VERSION "f33"
NS_ :

BS_:
BU_: RR RL FL FR GEN

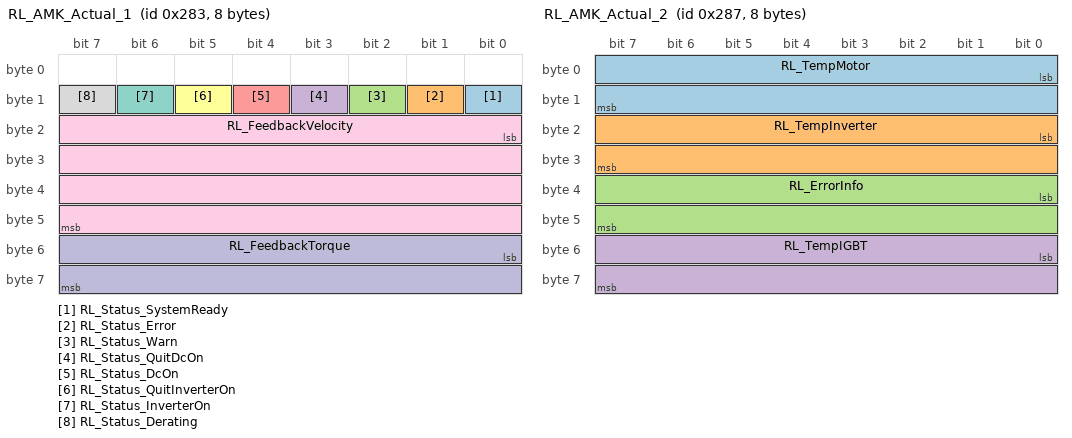
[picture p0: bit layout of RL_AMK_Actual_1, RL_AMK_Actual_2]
BO_ 643 RL_AMK_Actual_1: 8 RL
 SG_ RL_Status_SystemReady : 8|1@1+ (1,0) [0|1] "" Vector__XXX
 SG_ RL_Status_Error : 9|1@1+ (1,0) [0|1] "" Vector__XXX
 SG_ RL_Status_Warn : 10|1@1+ (1,0) [0|1] "" Vector__XXX
 SG_ RL_Status_QuitDcOn : 11|1@1+ (1,0) [0|1] "" Vector__XXX
 SG_ RL_Status_DcOn : 12|1@1+ (1,0) [0|1] "" Vector__XXX
 SG_ RL_Status_QuitInverterOn : 13|1@1+ (1,0) [0|1] "" Vector__XXX
 SG_ RL_Status_InverterOn : 14|1@1+ (1,0) [0|1] "" Vector__XXX
 SG_ RL_Status_Derating : 15|1@1+ (1,0) [0|1] "" Vector__XXX
 SG_ RL_FeedbackVelocity : 16|32@1- (0.0001,0) [-100000.0|100000.0] "rpm" Vector__XXX
 SG_ RL_FeedbackTorque : 48|16@1- (0.1,0) [-3000.0|3000.0] "% Mn" Vector__XXX

BO_ 647 RL_AMK_Actual_2: 8 RL
 SG_ RL_TempMotor : 0|16@1- (0.1,0) [-3276.8|3276.7] "degC" Vector__XXX
 SG_ RL_TempInverter : 16|16@1- (0.1,0) [-3276.8|3276.7] "" Vector__XXX
 SG_ RL_ErrorInfo : 32|16@1+ (1,0) [0|65535] "" Vector__XXX
 SG_ RL_TempIGBT : 48|16@1- (0.1,0) [-3276.8|3276.7] "" Vector__XXX

BO_ 657 RL_AMK_RITSet1: 8 RL
 SG_ RL_ErrorList1 : 0|32@1+ (1,0) [0|0] "" Vector__XXX
 SG_ RL_ErrorList2 : 32|32@1+ (1,0) [0|0] "" Vector__XXX

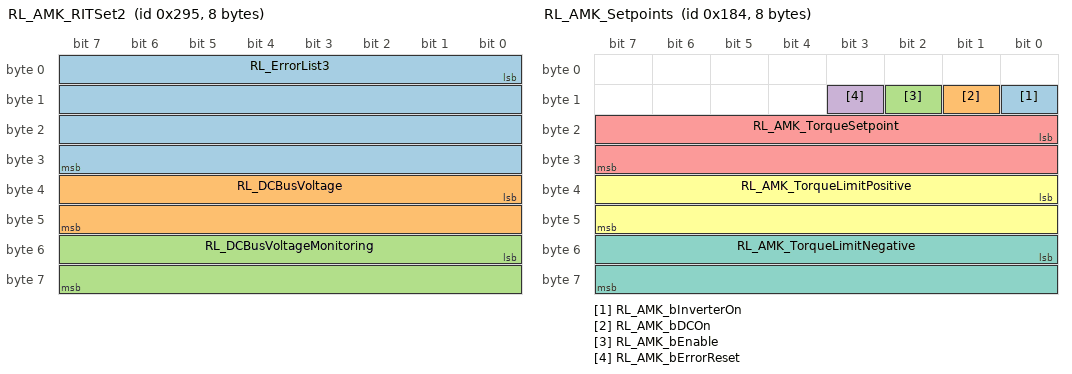
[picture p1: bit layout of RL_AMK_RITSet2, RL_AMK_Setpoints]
BO_ 661 RL_AMK_RITSet2: 8 RL
 SG_ RL_ErrorList3 : 0|32@1+ (1,0) [0|0] "" Vector__XXX
 SG_ RL_DCBusVoltage : 32|16@1+ (1,0) [0|4096] "V" Vector__XXX
 SG_ RL_DCBusVoltageMonitoring : 48|16@1+ (0.1,0) [0|4096] "V" Vector__XXX

BO_ 665 RL_AMK_RITSet3: 4 RL
 SG_ RL_ActivePower : 0|32@1- (1,0) [-2147483648|2147483647] "W" Vector__XXX

BO_ 669 RL_AMK_RITSet4: 4 RL
 SG_ RL_ActualPowerBipolar : 0|32@1- (1,0) [0|0] "W" Vector__XXX

BO_ 673 RL_AMK_RIT_Set5: 4 RL
 SG_ RL_MagnetizingCurrent: 0|32@1- (0.001,0) [0|0] "A" Vector__XXX

BO_ 677 RL_AMK_RIT_Set6: 4 RL
 SG_ RL_TorqueCurrentFeedback: 0|32@1- (0.001,0) [0|0] "A" Vector__XXX

BO_ 388 RL_AMK_Setpoints: 8 RL
 SG_ RL_AMK_bInverterOn : 8|1@1+ (1,0) [0|1] "" Vector__XXX
 SG_ RL_AMK_bDCOn : 9|1@1+ (1,0) [0|1] "" Vector__XXX
 SG_ RL_AMK_bEnable : 10|1@1+ (1,0) [0|1] "" Vector__XXX
 SG_ RL_AMK_bErrorReset : 11|1@1+ (1,0) [0|1] "" Vector__XXX
 SG_ RL_AMK_TorqueSetpoint : 16|16@1- (0.1, 0) [-1000|1000] "% Mn" Vector__XXX
 SG_ RL_AMK_TorqueLimitPositive : 32|16@1- (0.1, 0) [-3000|3000] "% Mn" Vector__XXX
 SG_ RL_AMK_TorqueLimitNegative : 48|16@1- (0.1, 0) [-3000|3000] "% Mn" Vector__XXX

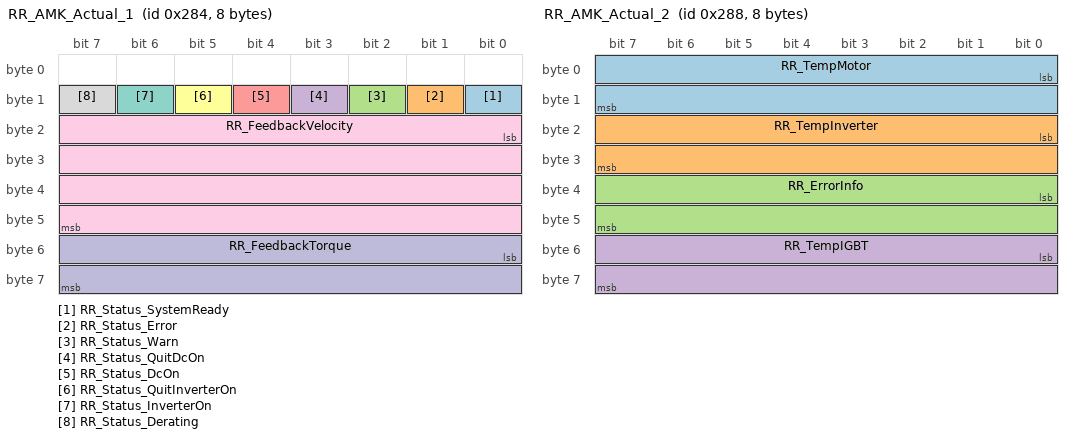
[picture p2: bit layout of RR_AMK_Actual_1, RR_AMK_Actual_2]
BO_ 644 RR_AMK_Actual_1: 8 RR
 SG_ RR_Status_SystemReady : 8|1@1+ (1,0) [0|1] "" Vector__XXX
 SG_ RR_Status_Error : 9|1@1+ (1,0) [0|1] "" Vector__XXX
 SG_ RR_Status_Warn : 10|1@1+ (1,0) [0|1] "" Vector__XXX
 SG_ RR_Status_QuitDcOn : 11|1@1+ (1,0) [0|1] "" Vector__XXX
 SG_ RR_Status_DcOn : 12|1@1+ (1,0) [0|1] "" Vector__XXX
 SG_ RR_Status_QuitInverterOn : 13|1@1+ (1,0) [0|1] "" Vector__XXX
 SG_ RR_Status_InverterOn : 14|1@1+ (1,0) [0|1] "" Vector__XXX
 SG_ RR_Status_Derating : 15|1@1+ (1,0) [0|1] "" Vector__XXX
 SG_ RR_FeedbackVelocity : 16|32@1- (0.0001,0) [-100000.0|100000.0] "rpm" Vector__XXX
 SG_ RR_FeedbackTorque : 48|16@1- (0.1,0) [-3000.0|3000.0] "% Mn" Vector__XXX

BO_ 648 RR_AMK_Actual_2: 8 RR
 SG_ RR_TempMotor : 0|16@1- (0.1,0) [-3276.8|3276.7] "degC" Vector__XXX
 SG_ RR_TempInverter : 16|16@1- (0.1,0) [-3276.8|3276.7] "" Vector__XXX
 SG_ RR_ErrorInfo : 32|16@1+ (1,0) [0|65535] "" Vector__XXX
 SG_ RR_TempIGBT : 48|16@1- (0.1,0) [-3276.8|3276.7] "" Vector__XXX

BO_ 658 RR_AMK_RITSet1: 8 RR
 SG_ RR_ErrorList1 : 0|32@1+ (1,0) [0|0] "" Vector__XXX
 SG_ RR_ErrorList2 : 32|32@1+ (1,0) [0|0] "" Vector__XXX

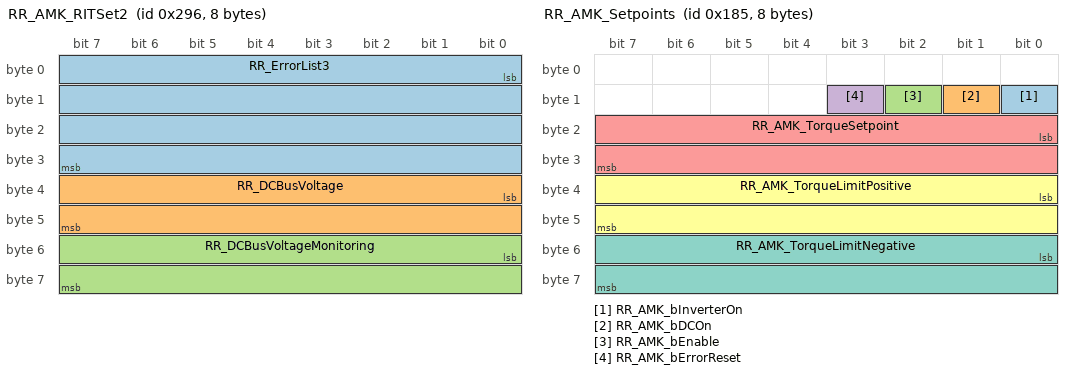
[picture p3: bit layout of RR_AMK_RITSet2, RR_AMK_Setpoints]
BO_ 662 RR_AMK_RITSet2: 8 RR
 SG_ RR_ErrorList3 : 0|32@1+ (1,0) [0|0] "" Vector__XXX
 SG_ RR_DCBusVoltage : 32|16@1+ (1,0) [0|4096] "V" Vector__XXX
 SG_ RR_DCBusVoltageMonitoring : 48|16@1+ (0.1,0) [0|4096] "V" Vector__XXX

BO_ 666 RR_AMK_RITSet3: 4 RR
 SG_ RR_ActivePower : 0|32@1- (1,0) [-2147483648|2147483647] "W" Vector__XXX

BO_ 670 RR_AMK_RITSet4: 4 RR
 SG_ RR_ActualPowerBipolar : 0|32@1- (1,0) [0|0] "W" Vector__XXX

BO_ 674 RR_AMK_RIT_Set5: 4 RR
 SG_ RR_MagnetizingCurrent: 0|32@1- (0.001,0) [0|0] "A" Vector__XXX

BO_ 678 RR_AMK_RIT_Set6: 4 RR
 SG_ RR_TorqueCurrentFeedback: 0|32@1- (0.001,0) [0|0] "A" Vector__XXX

BO_ 389 RR_AMK_Setpoints: 8 RR
 SG_ RR_AMK_bInverterOn : 8|1@1+ (1,0) [0|1] "" Vector__XXX
 SG_ RR_AMK_bDCOn : 9|1@1+ (1,0) [0|1] "" Vector__XXX
 SG_ RR_AMK_bEnable : 10|1@1+ (1,0) [0|1] "" Vector__XXX
 SG_ RR_AMK_bErrorReset : 11|1@1+ (1,0) [0|1] "" Vector__XXX
 SG_ RR_AMK_TorqueSetpoint : 16|16@1- (0.1, 0) [-1000|1000] "% Mn" Vector__XXX
 SG_ RR_AMK_TorqueLimitPositive : 32|16@1- (0.1, 0) [-3000|3000] "% Mn" Vector__XXX
 SG_ RR_AMK_TorqueLimitNegative : 48|16@1- (0.1, 0) [-3000|3000] "% Mn" Vector__XXX

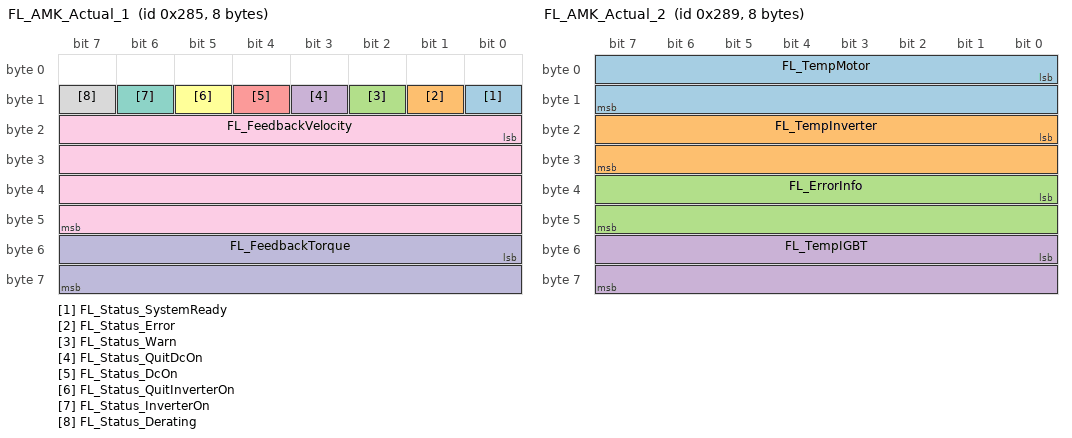
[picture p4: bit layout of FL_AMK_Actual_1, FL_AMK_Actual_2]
BO_ 645 FL_AMK_Actual_1: 8 FL
 SG_ FL_Status_SystemReady : 8|1@1+ (1,0) [0|1] "" Vector__XXX
 SG_ FL_Status_Error : 9|1@1+ (1,0) [0|1] "" Vector__XXX
 SG_ FL_Status_Warn : 10|1@1+ (1,0) [0|1] "" Vector__XXX
 SG_ FL_Status_QuitDcOn : 11|1@1+ (1,0) [0|1] "" Vector__XXX
 SG_ FL_Status_DcOn : 12|1@1+ (1,0) [0|1] "" Vector__XXX
 SG_ FL_Status_QuitInverterOn : 13|1@1+ (1,0) [0|1] "" Vector__XXX
 SG_ FL_Status_InverterOn : 14|1@1+ (1,0) [0|1] "" Vector__XXX
 SG_ FL_Status_Derating : 15|1@1+ (1,0) [0|1] "" Vector__XXX
 SG_ FL_FeedbackVelocity : 16|32@1- (0.0001,0) [-100000.0|100000.0] "rpm" Vector__XXX
 SG_ FL_FeedbackTorque : 48|16@1- (0.1,0) [-3000.0|3000.0] "% Mn" Vector__XXX

BO_ 649 FL_AMK_Actual_2: 8 FL
 SG_ FL_TempMotor : 0|16@1- (0.1,0) [-3276.8|3276.7] "degC" Vector__XXX
 SG_ FL_TempInverter : 16|16@1- (0.1,0) [-3276.8|3276.7] "" Vector__XXX
 SG_ FL_ErrorInfo : 32|16@1+ (1,0) [0|65535] "" Vector__XXX
 SG_ FL_TempIGBT : 48|16@1- (0.1,0) [-3276.8|3276.7] "" Vector__XXX

BO_ 659 FL_AMK_RITSet1: 8 FL
 SG_ FL_ErrorList1 : 0|32@1+ (1,0) [0|0] "" Vector__XXX
 SG_ FL_ErrorList2 : 32|32@1+ (1,0) [0|0] "" Vector__XXX

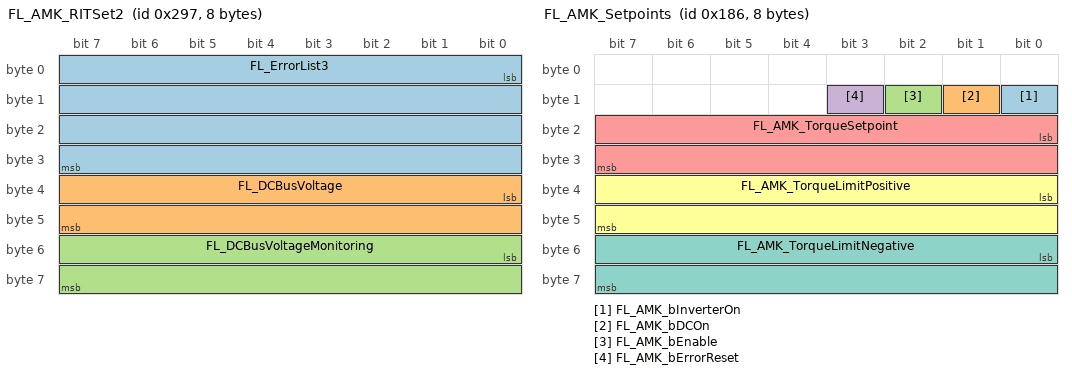
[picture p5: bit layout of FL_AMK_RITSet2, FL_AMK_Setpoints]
BO_ 663 FL_AMK_RITSet2: 8 FL
 SG_ FL_ErrorList3 : 0|32@1+ (1,0) [0|0] "" Vector__XXX
 SG_ FL_DCBusVoltage : 32|16@1+ (1,0) [0|4096] "V" Vector__XXX
 SG_ FL_DCBusVoltageMonitoring : 48|16@1+ (0.1,0) [0|4096] "V" Vector__XXX

BO_ 667 FL_AMK_RITSet3: 4 FL
 SG_ FL_ActivePower : 0|32@1- (1,0) [-2147483648|2147483647] "W" Vector__XXX

BO_ 671 FL_AMK_RITSet4: 4 FL
 SG_ FL_ActualPowerBipolar : 0|32@1- (1,0) [0|0] "W" Vector__XXX

BO_ 675 FL_AMK_RIT_Set5: 4 FL
 SG_ FL_MagnetizingCurrent: 0|32@1- (0.001,0) [0|0] "A" Vector__XXX

BO_ 679 FL_AMK_RIT_Set6: 4 FL
 SG_ FL_TorqueCurrentFeedback: 0|32@1- (0.001,0) [0|0] "A" Vector__XXX

BO_ 390 FL_AMK_Setpoints: 8 FL
 SG_ FL_AMK_bInverterOn : 8|1@1+ (1,0) [0|1] "" Vector__XXX
 SG_ FL_AMK_bDCOn : 9|1@1+ (1,0) [0|1] "" Vector__XXX
 SG_ FL_AMK_bEnable : 10|1@1+ (1,0) [0|1] "" Vector__XXX
 SG_ FL_AMK_bErrorReset : 11|1@1+ (1,0) [0|1] "" Vector__XXX
 SG_ FL_AMK_TorqueSetpoint : 16|16@1- (0.1, 0) [-1000|1000] "% Mn" Vector__XXX
 SG_ FL_AMK_TorqueLimitPositive : 32|16@1- (0.1, 0) [-3000|3000] "% Mn" Vector__XXX
 SG_ FL_AMK_TorqueLimitNegative : 48|16@1- (0.1, 0) [-3000|3000] "% Mn" Vector__XXX

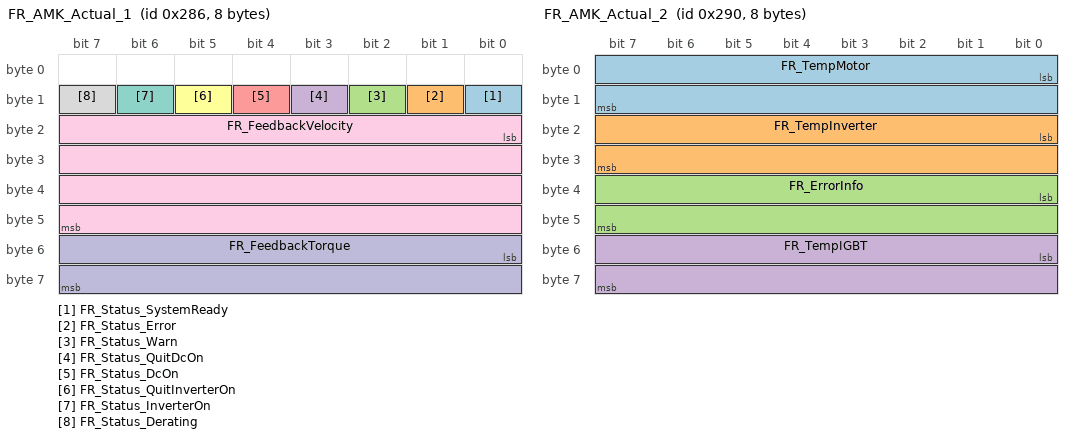
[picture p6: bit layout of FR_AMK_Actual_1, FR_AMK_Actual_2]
BO_ 646 FR_AMK_Actual_1: 8 FR
 SG_ FR_Status_SystemReady : 8|1@1+ (1,0) [0|1] "" Vector__XXX
 SG_ FR_Status_Error : 9|1@1+ (1,0) [0|1] "" Vector__XXX
 SG_ FR_Status_Warn : 10|1@1+ (1,0) [0|1] "" Vector__XXX
 SG_ FR_Status_QuitDcOn : 11|1@1+ (1,0) [0|1] "" Vector__XXX
 SG_ FR_Status_DcOn : 12|1@1+ (1,0) [0|1] "" Vector__XXX
 SG_ FR_Status_QuitInverterOn : 13|1@1+ (1,0) [0|1] "" Vector__XXX
 SG_ FR_Status_InverterOn : 14|1@1+ (1,0) [0|1] "" Vector__XXX
 SG_ FR_Status_Derating : 15|1@1+ (1,0) [0|1] "" Vector__XXX
 SG_ FR_FeedbackVelocity : 16|32@1- (0.0001,0) [-100000.0|100000.0] "rpm" Vector__XXX
 SG_ FR_FeedbackTorque : 48|16@1- (0.1,0) [-3000.0|3000.0] "% Mn" Vector__XXX

BO_ 656 FR_AMK_Actual_2: 8 FR
 SG_ FR_TempMotor : 0|16@1- (0.1,0) [-3276.8|3276.7] "degC" Vector__XXX
 SG_ FR_TempInverter : 16|16@1- (0.1,0) [-3276.8|3276.7] "" Vector__XXX
 SG_ FR_ErrorInfo : 32|16@1+ (1,0) [0|65535] "" Vector__XXX
 SG_ FR_TempIGBT : 48|16@1- (0.1,0) [-3276.8|3276.7] "" Vector__XXX

BO_ 660 FR_AMK_RITSet1: 8 FR
 SG_ FR_ErrorList1 : 0|32@1+ (1,0) [0|0] "" Vector__XXX
 SG_ FR_ErrorList2 : 32|32@1+ (1,0) [0|0] "" Vector__XXX

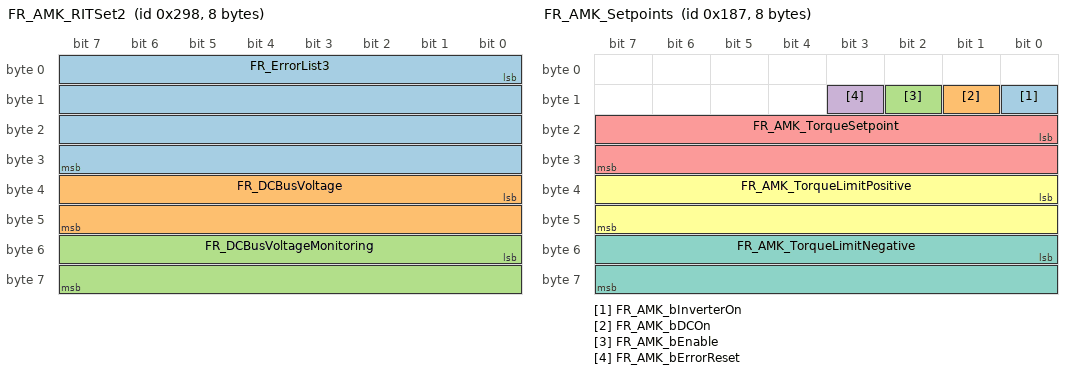
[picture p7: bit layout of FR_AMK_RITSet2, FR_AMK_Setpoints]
BO_ 664 FR_AMK_RITSet2: 8 FR
 SG_ FR_ErrorList3 : 0|32@1+ (1,0) [0|0] "" Vector__XXX
 SG_ FR_DCBusVoltage : 32|16@1+ (1,0) [0|4096] "V" Vector__XXX
 SG_ FR_DCBusVoltageMonitoring : 48|16@1+ (0.1,0) [0|4096] "V" Vector__XXX

BO_ 668 FR_AMK_RITSet3: 4 FR
 SG_ FR_ActivePower : 0|32@1- (1,0) [-2147483648|2147483647] "W" Vector__XXX

BO_ 672 FR_AMK_RITSet4: 4 FR
 SG_ FR_ActualPowerBipolar : 0|32@1- (1,0) [0|0] "W" Vector__XXX

BO_ 676 FR_AMK_RIT_Set5: 4 FR
 SG_ FR_MagnetizingCurrent: 0|32@1- (0.001,0) [0|0] "A" Vector__XXX

BO_ 680 FR_AMK_RIT_Set6: 4 FR
 SG_ FR_TorqueCurrentFeedback: 0|32@1- (0.001,0) [0|0] "A" Vector__XXX

BO_ 391 FR_AMK_Setpoints: 8 FR
 SG_ FR_AMK_bInverterOn : 8|1@1+ (1,0) [0|1] "" Vector__XXX
 SG_ FR_AMK_bDCOn : 9|1@1+ (1,0) [0|1] "" Vector__XXX
 SG_ FR_AMK_bEnable : 10|1@1+ (1,0) [0|1] "" Vector__XXX
 SG_ FR_AMK_bErrorReset : 11|1@1+ (1,0) [0|1] "" Vector__XXX
 SG_ FR_AMK_TorqueSetpoint : 16|16@1- (0.1, 0) [-1000|1000] "% Mn" Vector__XXX
 SG_ FR_AMK_TorqueLimitPositive : 32|16@1- (0.1, 0) [-3000|3000] "% Mn" Vector__XXX
 SG_ FR_AMK_TorqueLimitNegative : 48|16@1- (0.1, 0) [-3000|3000] "% Mn" Vector__XXX

CM_ "Dummy messages for use in the C files. These will never be sent over CAN,
    it is only to make the C code more generic";

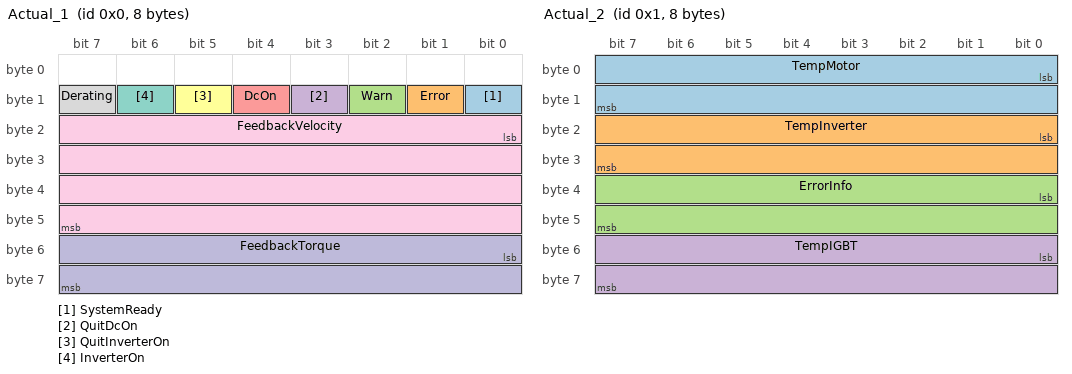
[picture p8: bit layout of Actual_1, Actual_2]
BO_ 000 Actual_1: 8 GEN
 SG_ SystemReady : 8|1@1+ (1,0) [0|1] "" Vector__XXX
 SG_ Error : 9|1@1+ (1,0) [0|1] "" Vector__XXX
 SG_ Warn : 10|1@1+ (1,0) [0|1] "" Vector__XXX
 SG_ QuitDcOn : 11|1@1+ (1,0) [0|1] "" Vector__XXX
 SG_ DcOn : 12|1@1+ (1,0) [0|1] "" Vector__XXX
 SG_ QuitInverterOn : 13|1@1+ (1,0) [0|1] "" Vector__XXX
 SG_ InverterOn : 14|1@1+ (1,0) [0|1] "" Vector__XXX
 SG_ Derating : 15|1@1+ (1,0) [0|1] "" Vector__XXX
 SG_ FeedbackVelocity : 16|32@1- (0.0001,0) [-100000.0|100000.0] "rpm" Vector__XXX
 SG_ FeedbackTorque : 48|16@1- (0.1,0) [-3000.0|3000.0] "% Mn" Vector__XXX

BO_ 001 Actual_2: 8 GEN
 SG_ TempMotor : 0|16@1- (0.1,0) [-3276.8|3276.7] "degC" Vector__XXX
 SG_ TempInverter : 16|16@1- (0.1,0) [-3276.8|3276.7] "" Vector__XXX
 SG_ ErrorInfo : 32|16@1+ (1,0) [0|65535] "" Vector__XXX
 SG_ TempIGBT : 48|16@1- (0.1,0) [-3276.8|3276.7] "" Vector__XXX

BO_ 002 RITSet1: 8 GEN
 SG_ ErrorList1 : 0|32@1+ (1,0) [0|0] "" Vector__XXX
 SG_ ErrorList2 : 32|32@1+ (1,0) [0|0] "" Vector__XXX

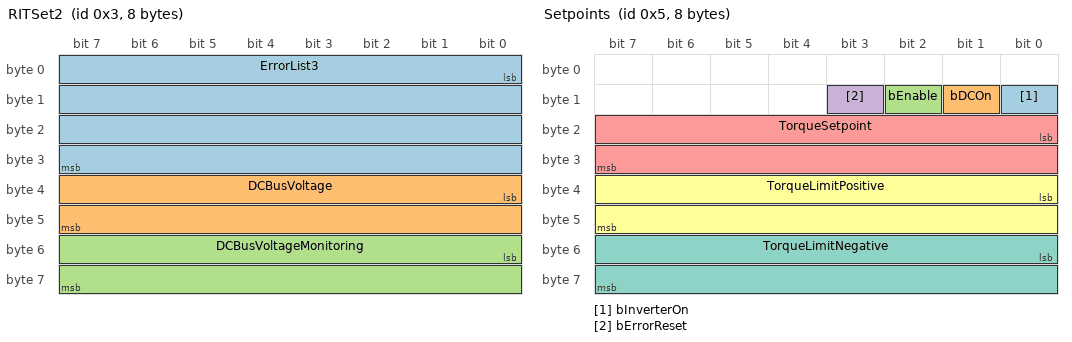
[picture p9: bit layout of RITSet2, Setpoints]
BO_ 003 RITSet2: 8 GEN
 SG_ ErrorList3 : 0|32@1+ (1,0) [0|0] "" Vector__XXX
 SG_ DCBusVoltage : 32|16@1+ (1,0) [0|4096] "V" Vector__XXX
 SG_ DCBusVoltageMonitoring : 48|16@1+ (0.1,0) [0|4096] "V" Vector__XXX

BO_ 004 RITSet3: 4 GEN
 SG_ ActivePower : 0|32@1- (1, 0) [-2147483648|2147483647] "W" Vector__XXX

BO_ 005 Setpoints: 8 GEN
 SG_ bInverterOn : 8|1@1+ (1,0) [0|1] "" Vector__XXX
 SG_ bDCOn : 9|1@1+ (1,0) [0|1] "" Vector__XXX
 SG_ bEnable : 10|1@1+ (1,0) [0|1] "" Vector__XXX
 SG_ bErrorReset : 11|1@1+ (1,0) [0|1] "" Vector__XXX
 SG_ TorqueSetpoint : 16|16@1- (0.1, 0) [-1000|1000] "% Mn" Vector__XXX
 SG_ TorqueLimitPositive : 32|16@1- (0.1, 0) [-3000|3000] "% Mn" Vector__XXX
 SG_ TorqueLimitNegative : 48|16@1- (0.1, 0) [-3000|3000] "% Mn" Vector__XXX
